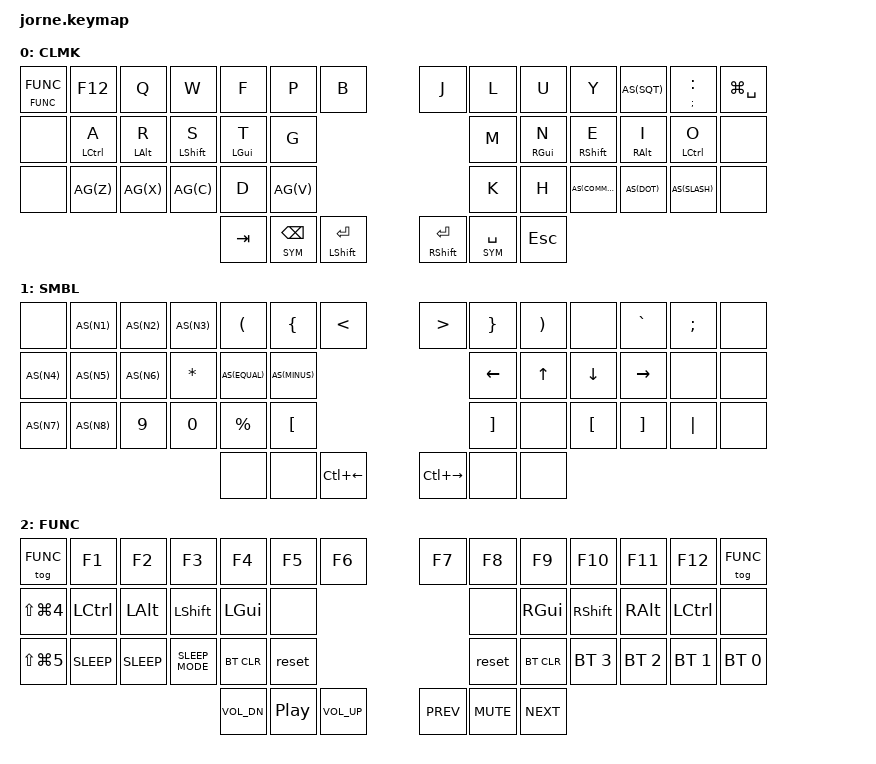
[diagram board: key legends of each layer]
/*
 * Copyright (c) 2020 The ZMK Contributors
 *
 * SPDX-License-Identifier: MIT
 */

#include <behaviors.dtsi>
#include <dt-bindings/zmk/keys.h>
#include <dt-bindings/zmk/bt.h>
   

#define TIMEOUT 100

#define COLEMAK  0
#define SYM      1
#define FUNC     2


#define XXX &none
#define ___ &trans

#define SA(key)  &kp LS(LA(key))
#define SG(key)  &kp LS(LG(key))
#define SC(key)  &kp LS(LC(key))

#define AS(key)  &as LS(key) key      // auto shift
#define AG(key)  &as RG(key) key      // auto cmd

#define ALF      &kp LG(SPACE)        // alfred

#define DSKT_L   &kp LC(LEFT)         // left desktop
#define DSKT_R   &kp LC(RIGHT)        // right desktop

#define MM_L     &kp LG(LA(LEFT))     // moom left
#define MM_R     &kp LG(LA(RIGHT))    // moom right
#define MM_F     &kp LG(LA(F))        // moom full screen

#define SCRNSHT &kp LS(LG(N5))
#define AREASHT &kp LS(LG(N4))
#define ALLSHT  &kp LS(LG(N3))

#define COL_SEM  &dtm SEMI COLON 
#define DOT_COM  &dtm COMMA DOT

&lt {
    quick-tap-ms = <180>;
};

&mt {
    quick-tap-ms = <180>;
};

/ {   
  behaviors {
    //&hm LGUI A
    hm: homerow_mods {
            compatible = "zmk,behavior-hold-tap";
            label = "HOMEROW_MODS";
            #binding-cells = <2>;
            tapping_term_ms = <250>;
            flavor = "tap-preferred";
            bindings = <&kp>, <&kp>;
    };
    //&lm SYM SYM
    lm: layer_mods {
		    compatible = "zmk,behavior-hold-tap";
		    label = "LAYER_MOD";
		    #binding-cells = <2>;
		    tapping-term-ms = <250>;
		    quick_tap_ms = <0>;
		    flavor = "tap-preferred";
		    bindings = <&mo>, <&tog>;
	};
    //&as LS(DOT) DOT
    as: auto_shift {
            compatible = "zmk,behavior-hold-tap";
            label = "AUTO_SHIFT";
            #binding-cells = <2>;
            tapping-term-ms = <200>;
            quick_tap_ms = <0>;
            flavor = "tap-preferred";
            bindings = <&kp>, <&kp>;
    };
    //&dtm COMMA DOT
    dtm: double_tap_mod {
			compatible = "zmk,behavior-hold-tap";
			label = "DOUBLE_TAP";
			#binding-cells = <2>;
			tapping_term_ms = <200>;
			quick_tap_ms = <200>;
			flavor = "balanced";
			bindings = <&kp>, <&kp>;
		};
  };
  // combos {
  //   #include "combos.dtsi"
  // };
  keymap {
       compatible = "zmk,keymap";
              COLEMAK {
              label = " CLMK";
              bindings = <
// ╭─────────────┬─────────────┬─────────────┬─────────────┬─────────────┬─────────────┬─────────────╮                              ╭─────────────┬─────────────┬─────────────┬─────────────┬─────────────┬─────────────┬──────────────╮ 
    &lm FUNC FUNC    &kp F12        &kp Q         &kp W         &kp F         &kp P         &kp B                                        &kp J        &kp L          &kp U         &kp Y        AS(SQT)      COL_SEM          ALF
// ╰─────────────┼─────────────┼─────────────┼─────────────┼─────────────┼─────────────┼─────────────┤                              ├─────────────┼─────────────┼─────────────┼─────────────┼─────────────┼─────────────┼──────────────╯ 
                       XXX       &hm LCTRL A   &hm LALT R    &hm LSHFT S    &hm LGUI T      &kp G                                        &kp M      &hm RGUI N    &hm RSHFT E    &hm RALT I   &hm LCTRL O      XXX 
//               ├─────────────┼─────────────┼─────────────┼─────────────┼─────────────┼─────────────┤                              ├─────────────┼─────────────┼─────────────┼─────────────┼─────────────┼─────────────┤
                       XXX          AG(Z)         AG(X)         AG(C)         &kp D         AG(V)                                        &kp K        &kp H       AS(COMMA)      AS(DOT)      AS(SLASH)        XXX
//               ╰─────────────┴─────────────┴─────────────┴─────────────┼─────────────┼─────────────┼─────────────╮  ╭─────────────┼─────────────┼─────────────┼─────────────┴─────────────┴─────────────┴─────────────╯
                                                                             &kp TAB     &lt SYM BSPC  &mt LSHFT RET    &mt RSHFT RET &lt SYM SPACE   &kp ESC
//                                                                       ╰─────────────┴─────────────┴─────────────╯  ╰─────────────┴─────────────┴─────────────╯
                           >;
              };
              SYM {
              label = " SMBL";
              bindings = <
// ╭─────────────┬─────────────┬─────────────┬─────────────┬─────────────┬─────────────┬─────────────╮                              ╭─────────────┬─────────────┬─────────────┬─────────────┬─────────────┬─────────────┬──────────────╮ 
          XXX        AS(N1)         AS(N2)        AS(N3)       &kp LPAR      &kp LBRC       &kp LT                                      &kp GT       &kp RBRC       &kp RPAR        XXX       &kp GRAVE     &kp SEMI          XXX     
// ╰─────────────┼─────────────┼─────────────┼─────────────┼─────────────┼─────────────┼─────────────┤                              ├─────────────┼─────────────┼─────────────┼─────────────┼─────────────┼─────────────┼──────────────╯ 
                     AS(N4)         AS(N5)        AS(N6)       &kp STAR     AS(EQUAL)     AS(MINUS)                                     &kp LEFT      &kp UP        &kp DOWN     &kp RIGHT        XXX           XXX  
//               ├─────────────┼─────────────┼─────────────┼─────────────┼─────────────┼─────────────┤                              ├─────────────┼─────────────┼─────────────┼─────────────┼─────────────┼─────────────┤
                     AS(N7)         AS(N8)        &kp N9        &kp N0      &kp PRCNT      &kp LBKT                                     &kp RBKT       XXX          &kp LBKT      &kp RBKT      &kp PIPE        XXX
//               ╰─────────────┴─────────────┴─────────────┴─────────────┼─────────────┼─────────────┼─────────────╮  ╭─────────────┼─────────────┼─────────────┼─────────────┴─────────────┴─────────────┴─────────────╯
                                                                              XXX            XXX         DSKT_L          DSKT_R          XXX          XXX  
//                                                                       ╰─────────────┴─────────────┴─────────────╯  ╰─────────────┴─────────────┴─────────────╯
                          >;
              };
              FUNC {
              label = " FUNC";
              bindings = <
// ╭─────────────┬─────────────┬─────────────┬─────────────┬─────────────┬─────────────┬─────────────╮                              ╭─────────────┬─────────────┬─────────────┬─────────────┬─────────────┬─────────────┬──────────────╮ 
      &tog FUNC      &kp F1        &kp F2        &kp F3        &kp F4        &kp F5        &kp F6                                       &kp F7        &kp F8        &kp F9        &kp F10      &kp F11       &kp F12       &tog FUNC 
// ╰─────────────┼─────────────┼─────────────┼─────────────┼─────────────┼─────────────┼─────────────┤                              ├─────────────┼─────────────┼─────────────┼─────────────┼─────────────┼─────────────┼──────────────╯ 
                    AREASHT       &kp LCTRL     &kp LALT      &kp LSHFT      &kp LGUI       XXX                                           XXX        &kp RGUI     &kp RSHFT      &kp RALT     &kp LCTRL        XXX                                                                                                                                                               
//               ├─────────────┼─────────────┼─────────────┼─────────────┼─────────────┼─────────────┤                              ├─────────────┼─────────────┼─────────────┼─────────────┼─────────────┼─────────────┤
                    SCRNSHT     &kp C_SLEEP    &kp K_SLEEP &kp C_SLEEP_MODE &bt BT_CLR      &reset                                       &reset      &bt BT_CLR   &bt BT_SEL 3  &bt BT_SEL 2   &bt BT_SEL 1  &bt BT_SEL 0                                                              
//               ╰─────────────┴─────────────┴─────────────┴─────────────┼─────────────┼─────────────┼─────────────╮  ╭─────────────┼─────────────┼─────────────┼─────────────┴─────────────┴─────────────┴─────────────╯
                                                                           &kp C_VOL_DN   &kp C_PP    &kp C_VOL_UP      &kp C_PREV    &kp K_MUTE    &kp C_NEXT  
//                                                                       ╰─────────────┴─────────────┴─────────────╯  ╰─────────────┴─────────────┴─────────────╯
                          >;
              };
      };
};
